# MKV10Z7 register map
File version: 1.6
Registers are 32-bit, read-write, reset 0x0 unless marked. A register's access mark holds for its fields unless they carry their own. Offsets are from the block's base; [hi:lo] are bit positions; {n}, {i} and the like mark numbered series; 'fields as' and 'values as' point back to an identical list.

## SIM — System Integration Module
Base 0x40047000; register names take the prefix SIM_
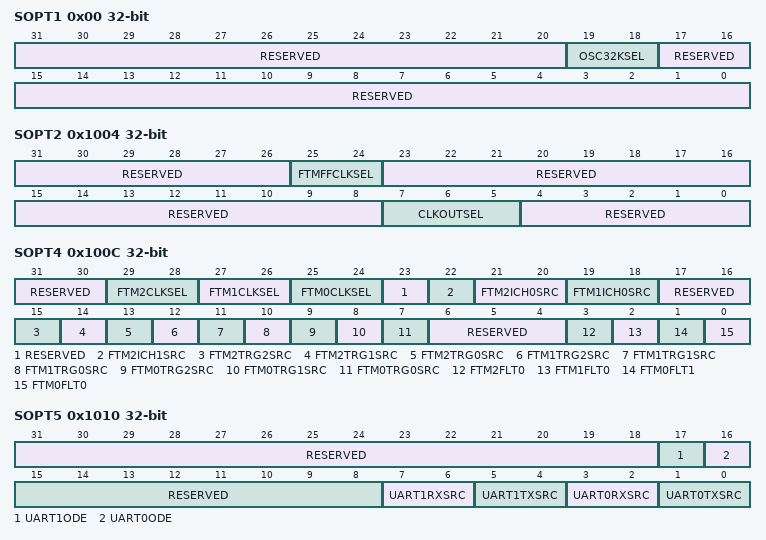
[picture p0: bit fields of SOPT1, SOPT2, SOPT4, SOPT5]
0x00 SOPT1 — System Options Register 1
  [31:20] RESERVED ro
  [19:18] OSC32KSEL — 32K Oscillator Clock Select
    0=System oscillator (OSC32KCLK); 3=LPO 1 kHz
  [17:0] RESERVED ro
0x1004 SOPT2 — System Options Register 2
  [31:26] RESERVED ro
  [25:24] FTMFFCLKSEL — FTM Fixed Frequency Clock Select
    0=MCGFFCLK; 1=MCGIRCLK; 2=OSCERCLK; 3=MCGFFCLK
  [23:8] RESERVED ro
  [7:5] CLKOUTSEL — CLKOUT Select
    2=Bus clock; 3=LPO clock (1 kHz); 4=MCGIRCLK; 6=OSCERCLK
  [4:0] RESERVED ro
0x100C SOPT4 — System Options Register 4
  [31:30] RESERVED ro
  [29:28] FTM2CLKSEL — FTM2 External Clock Pin Select
    0=FTM2 external clock driven by FTM_CLKIN0 pin; 1=FTM2 external clock driven by FTM_CLKIN1 pin; 2=FTM2 external clock driven by FTM_CLKIN2 pin
  [27:26] FTM1CLKSEL — FTM1 External Clock Pin Select
    0=FTM1 external clock driven by FTM_CLKIN0 pin; 1=FTM1 external clock driven by FTM_CLKIN1 pin; 2=FTM1 external clock driven by FTM_CLKIN2 pin
  [25:24] FTM0CLKSEL — FTM0 External Clock Pin Select
    0=FTM0 external clock driven by FTM_CLKIN0 pin; 1=FTM0 external clock driven by FTM_CLKIN1 pin; 2=FTM0 external clock driven by FTM_CLKIN2 pin
  [23] RESERVED ro
  [22] FTM2ICH1SRC — FTM2 Channel 1 Input Capture Source Select
    0=FTM2_CH1 pin is fed to FTM2 CH1; 1=FTM2_CH1 pin XOR FTM2_CH0 pin XOR FTM1_CH1 pin is fed to FTM2 CH1 If this field is set, then the three input pins feed FTM2 channel 1 input capture. In this case, FTM1 channel 1 cannot be used for input capture of FTM1, as it has no pin. FTM1 channel1 can be used for Output Compare mode of FTM1, though without an output.
  [21:20] FTM2ICH0SRC — FTM2 Channel 0 Input Capture Source Select
    0=FTM2_CH0 signal; 1=CMP0 output; 2=CMP1 output
  [19:18] FTM1ICH0SRC — FTM1 Channel 0 Input Capture Source Select
    0=FTM1_CH0 signal; 1=CMP0 output; 2=CMP1 output
  [17:16] RESERVED ro
  [15] FTM2TRG2SRC — FlexTimer 2 Hardware Trigger 2 Source Select
    0=HSCMP0 output drives FTM2 hardware trigger 2; 1=HSCMP1 output drives FTM2 hardware trigger 2
  [14] FTM2TRG1SRC — FlexTimer 2 Hardware Trigger 1 Source Select
    0=PDB output trigger 1 drives FTM2 hardware trigger 1; 1=FTM1 channel match drives FTM2 hardware trigger 1
  [13] FTM2TRG0SRC — FlexTimer 2 Hardware Trigger 0 Source Select
    0=HSCMP0 output drives FTM2 hardware trigger 0; 1=FTM0 channel match drives FTM2 hardware trigger 0
  [12] FTM1TRG2SRC — FlexTimer 1 Hardware Trigger 2 Source Select
    0=HSCMP0 output drives FTM1 hardware trigger 2; 1=HSCMP1 output drives FTM1 hardware trigger 2
  [11] FTM1TRG1SRC — FlexTimer 1 Hardware Trigger 1 Source Select
    0=PDB channel 1 trigger drives FTM1 hardware trigger 1; 1=FTM2 channel match drives FTM1 hardware trigger 1
  [10] FTM1TRG0SRC — FlexTimer 1 Hardware Trigger 0 Source Select
    0=HSCMP0 output drives FTM1 hardware trigger 0; 1=FTM0 channel match drives FTM1 hardware trigger 0
  [9] FTM0TRG2SRC — FlexTimer 0 Hardware Trigger 2 Source Select
    0=HSCMP0 output drives FTM0 hardware trigger 2; 1=HSCMP1 output drives FTM0 hardware trigger 2
  [8] FTM0TRG1SRC — FlexTimer 0 Hardware Trigger 1 Source Select
    0=PDB channel 1 trigger drives FTM0 hardware trigger 1; 1=FTM2 channel match drives FTM0 hardware trigger 1
  [7] FTM0TRG0SRC — FlexTimer 0 Hardware Trigger 0 Source Select
    0=HSCMP0 output drives FTM0 hardware trigger 0; 1=FTM1 channel match drives FTM0 hardware trigger 0
  [6:4] RESERVED ro
  [3] FTM2FLT0 — FTM2 Fault 0 Select
    0=FTM2_FLT0 pin; 1=CMP0 out
  [2] FTM1FLT0 — FTM1 Fault 0 Select
    0=FTM1_FLT0 pin; 1=CMP0 out
  [1] FTM0FLT1 — FTM0 Fault 1 Select
    0=FTM0_FLT1 pin; 1=CMP1 out
  [0] FTM0FLT0 — FTM0 Fault 0 Select
    0=FTM0_FLT0 pin; 1=CMP0 out
0x1010 SOPT5 — System Options Register 5
  [31:18] RESERVED
  [17] UART1ODE — UART1 Open Drain Enable
    0=Open drain is disabled on UART1; 1=Open drain is enabled on UART1
  [16] UART0ODE — UART0 Open Drain Enable
    0=Open drain is disabled on UART0; 1=Open drain is enabled on UART0
  [15:8] RESERVED ro
  [7:6] UART1RXSRC — UART 1 Receive Data Source Select
    0=UART1_RX pin; 1=CMP0; 2=CMP1
  [5:4] UART1TXSRC — UART 1 Transmit Data Source Select
    0=UART1_TX pin; 1=UART1_TX pin modulated with FTM1 channel 0 output; 2=UART1_TX pin modulated with FTM2 channel 0 output
  [3:2] UART0RXSRC — UART 0 Receive Data Source Select
    0=UART0_RX pin; 1=CMP0; 2=CMP1
  [1:0] UART0TXSRC — UART 0 Transmit Data Source Select
    0=UART0_TX pin; 1=UART0_TX pin modulated with FTM1 channel 0 output; 2=UART0_TX pin modulated with FTM2 channel 0 output
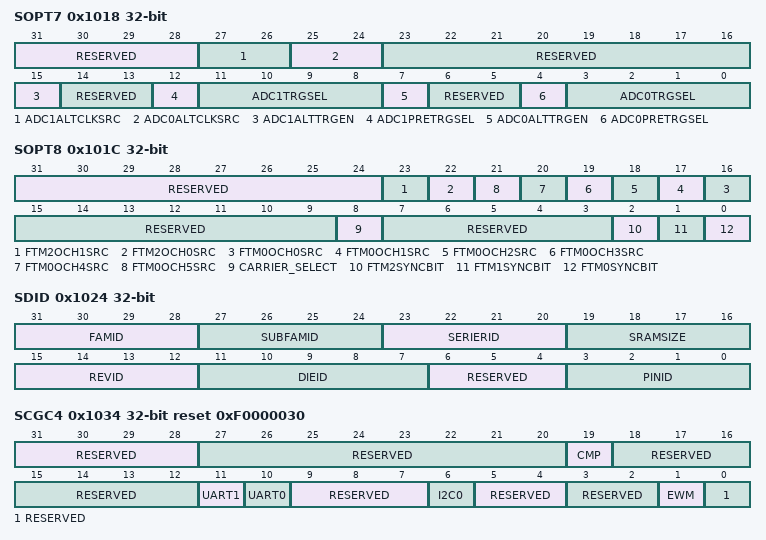
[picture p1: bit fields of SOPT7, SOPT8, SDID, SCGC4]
0x1018 SOPT7 — System Options Register 7
  [31:28] RESERVED ro
  [27:26] ADC1ALTCLKSRC — ADC1 ALT Clock Source Select
    0=OUTDIV5 output; 1=MCGIRCLK; 2=OSCERCLK
  [25:24] ADC0ALTCLKSRC — ADC0 ALT Clock Source Select
    0=OUTDIV5 output; 1=MCGIRCLK; 2=OSCERCLK
  [23:16] RESERVED ro
  [15] ADC1ALTTRGEN — ADC1 Alternate Trigger Enable
    0=PDB trigger selected for ADC1; 1=Alternate trigger selected for ADC1 as defined by ADC1TRGSEL
  [14:13] RESERVED ro
  [12] ADC1PRETRGSEL — ADC1 Pre-trigger Select
    0=Pre-trigger A for ADC1. Clearing this field will result in ADHWTSA=1 and ADHWTSB=0.; 1=Pre-trigger B for ADC1. Setting this bit will result in ADHWTSA=0 and ADHWTSB=1.
  [11:8] ADC1TRGSEL — ADC1 Trigger Select
    0=External trigger pin input (PDB0_EXTRG); 1=HSCMP0 output; 2=HSCMP1 output; {v}=DMA channel {v-4} transfer last write complete (v=4..7); 8=FTM0 overflow; 9=FTM1 overflow; 10=FTM2 overflow; 14=LPTMR0 trigger
  [7] ADC0ALTTRGEN — ADC0 Alternate Trigger Enable
    0=PDB trigger selected for ADC0; 1=Alternate trigger selected for ADC0 as defined by ADC0TRGSEL
  [6:5] RESERVED ro
  [4] ADC0PRETRGSEL — ADC0 Pre-trigger Select
    0=Pre-trigger A for ADC0. Clearing this field will result in ADHWTSA=1 and ADHWTSB=0.; 1=Pre-trigger B for ADC0. Setting this bit will result in ADHWTSA=0 and ADHWTSB=1.
  [3:0] ADC0TRGSEL — ADC0 Trigger Select
    values as ADC1TRGSEL
0x101C SOPT8 — System Options Register 8
  [31:24] RESERVED ro
  [23] FTM2OCH1SRC — FTM2 channel 1 output PWM/OCMP mode source select
    0=FTM2CH1 pin is the output of FTM2 channel 1 PWM/OCMP; 1=FTM2CH1 pin is the output of FTM2 channel 1 PWM/OCMP modulating the carrier frequency, as per CARRIER_SELECT
  [22] FTM2OCH0SRC — FTM2 channel 0 output PWM/OCMP mode source select
    0=FTM2CH0 pin is the output of FTM2 channel 0 PWM/OCMP; 1=FTM2CH0 pin is the output of FTM2 channel 0 PWM/OCMP modulating the carrier frequency, as per CARRIER_SELECT
  [n+16] FTM0OCH{n}SRC (n=0..5) — FTM0 channel {n} output PWM/OCMP mode source select
    0=FTM0CH{n} pin is the output of FTM0 channel {n} PWM/OCMP; 1=FTM0CH{n} pin is the output of FTM0 channel {n} PWM/OCMP modulating the carrier frequency, as per CARRIER_SELECT
  [15:9] RESERVED
  [8] CARRIER_SELECT — Carrier frequency selection for FTM0/2 output channel
    0=FTM1_CH1 output provides the carrier signal for Timer Modulation mode; 1=LPTMR0 prescaler output provides the carrier signal for Timer Modulation mode
  [7:3] RESERVED ro
  [2] FTM2SYNCBIT — FlexTimer 2 Hardware Trigger 0 configure by software
    0=No effect to FTM2; this allows the hardware trigger options to function as expected. See SOPT4[FTM2TRG0SRC].; 1=If TRIG0 is enabled, this refreshes the FTM2CNTIN and all buffered registers of the FTM2 (must write 0 first then write 1); this masks the hardware trigger
  [1] FTM1SYNCBIT — FlexTimer 1 Hardware Trigger 0 configure by software
    0=No effect to FTM1; this allows the hardware trigger options to function as expected. See SOPT4[FTM1TRG0SRC].; 1=If TRIG0 enabled, this refreshes the FTM1CNTIN and all buffered registers of the FTM1 (must write 0 first then write 1); this masks the hardware trigger
  [0] FTM0SYNCBIT — FlexTimer 0 Hardware Trigger 0 configure by software
    0=No effect to FTM0; this allow the hardware trigger options to function as expected. See SOPT4[FTM0TRG0SRC].; 1=If TRIG0 enabled, this refreshes the FTM0CNTIN and all buffered registers of the FTM0 (must write 0 first then write 1); this masks the hardware trigger
0x1024 SDID ro reset not defined — System Device Identification Register
  [31:28] FAMID — V-Family ID
    1=MKV10Zx
  [27:24] SUBFAMID — V Sub-family ID
    0=MKV10xxxx
  [23:20] SERIERID — Series ID
    6=V-family - Motor control
  [19:16] SRAMSIZE — System SRAM Size
    3=4 KB; 4=8 KB
  [15:12] REVID — Device revision number
  [11:7] DIEID — Device die number
  [6:4] RESERVED
  [3:0] PINID — Pincount identification
    2=32-pin; 3=44-pin; 4=48-pin
0x1034 SCGC4 reset 0xF0000030 — System Clock Gating Control Register 4
  [31:28] RESERVED ro
  [27:20] RESERVED ro
  [19] CMP — Comparator Clock Gate Control
    0=Clock disabled; 1=Clock enabled
  [18:12] RESERVED ro
  [11] UART1 — UART1 Clock Gate Control
    0=Clock disabled; 1=Clock enabled
  [10] UART0 — UART0 Clock Gate Control
    0=Clock disabled; 1=Clock enabled
  [9:7] RESERVED ro
  [6] I2C0 — I2C0 Clock Gate Control
    0=Clock disabled; 1=Clock enabled
  [5:4] RESERVED ro
  [3:2] RESERVED ro
  [1] EWM — EWM Clock Gate Control
    0=Clock disabled; 1=Clock enabled
  [0] RESERVED ro
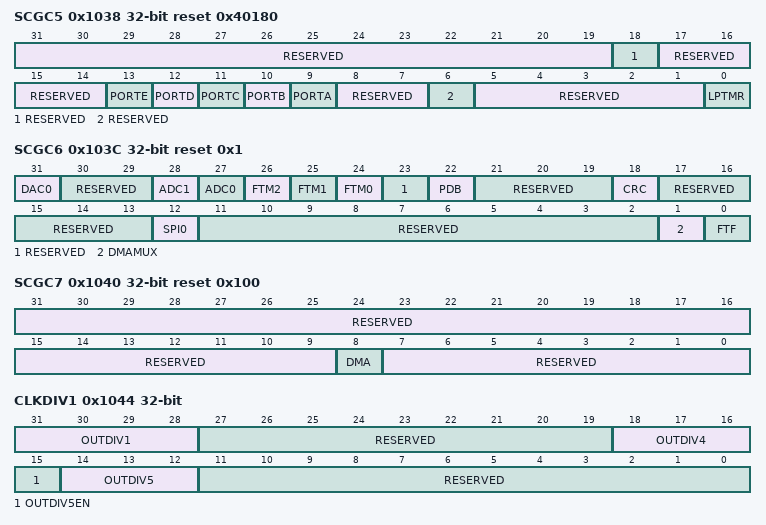
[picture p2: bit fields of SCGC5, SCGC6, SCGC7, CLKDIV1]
0x1038 SCGC5 reset 0x40180 — System Clock Gating Control Register 5
  [31:19] RESERVED ro
  [18] RESERVED ro
  [17:14] RESERVED ro
  [13] PORTE — Port E Clock Gate Control
    0=Clock disabled; 1=Clock enabled
  [12] PORTD — Port D Clock Gate Control
    0=Clock disabled; 1=Clock enabled
  [11] PORTC — Port C Clock Gate Control
    0=Clock disabled; 1=Clock enabled
  [10] PORTB — Port B Clock Gate Control
    0=Clock disabled; 1=Clock enabled
  [9] PORTA — Port A Clock Gate Control
    0=Clock disabled; 1=Clock enabled
  [8:7] RESERVED ro
  [6] RESERVED ro
  [5:1] RESERVED ro
  [0] LPTMR — Low Power Timer Clock Gate Control
    0=Access disabled; 1=Access enabled
0x103C SCGC6 reset 0x1 — System Clock Gating Control Register 6
  [31] DAC0 — DAC0 Clock Gate Control
    0=Clock disabled; 1=Clock enabled
  [30:29] RESERVED ro
  [28] ADC1 — ADC1 Clock Gate Control
    0=Clock disabled; 1=Clock enabled
  [27] ADC0 — ADC0 Clock Gate Control
    0=Clock disabled; 1=Clock enabled
  [26] FTM2 — FTM2 Clock Gate Control
    0=Clock disabled; 1=Clock enabled
  [25] FTM1 — FTM1 Clock Gate Control
    0=Clock disabled; 1=Clock enabled
  [24] FTM0 — FTM0 Clock Gate Control
    0=Clock disabled; 1=Clock enabled
  [23] RESERVED ro
  [22] PDB — PDB Clock Gate Control
    0=Clock disabled; 1=Clock enabled
  [21:19] RESERVED ro
  [18] CRC — CRC Clock Gate Control
    0=Clock disabled; 1=Clock enabled
  [17:13] RESERVED ro
  [12] SPI0 — SPI0 Clock Gate Control
    0=Clock disabled; 1=Clock enabled
  [11:2] RESERVED ro
  [1] DMAMUX — DMA Mux Clock Gate Control
    0=Clock disabled; 1=Clock enabled
  [0] FTF — Flash Memory Clock Gate Control
    0=Clock disabled; 1=Clock enabled
0x1040 SCGC7 reset 0x100 — System Clock Gating Control Register 7
  [31:9] RESERVED ro
  [8] DMA — DMA Clock Gate Control
    0=Clock disabled; 1=Clock enabled
  [7:0] RESERVED ro
0x1044 CLKDIV1 reset not defined — System Clock Divider Register 1
  [31:28] OUTDIV1 — Clock 1 Output Divider Value
    {v}=Divide-by-{v+1} (v=0..15)
  [27:19] RESERVED ro
  [18:16] OUTDIV4 — Clock 4 Output Divider Value
    {v}=Divide-by-{v+1} (v=0..7)
  [15] OUTDIV5EN — OUTDIV5 Divider Control
    0=OUTDIV5 disabled; 1=OUTDIV5 enabled
  [14:12] OUTDIV5 — Clock 5 Output Divider Value
    {v}=Divide-by-{v+1} (v=0..7)
  [11:0] RESERVED ro
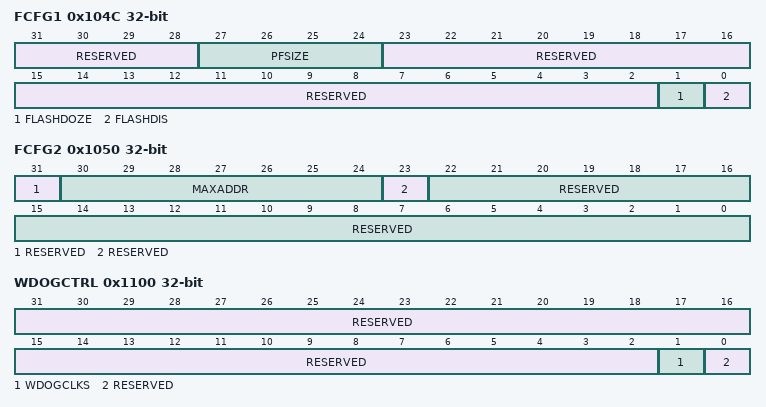
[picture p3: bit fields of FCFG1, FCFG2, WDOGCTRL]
0x104C FCFG1 reset not defined — Flash Configuration Register 1
  [31:28] RESERVED ro
  [27:24] PFSIZE ro — Program Flash Size
    0=8 KB of program flash memory, 0.25 KB protection region; 1=16 KB of program flash memory, 0.5 KB protection region; 3=32 KB of program flash memory, 1 KB protection region; 5=64 KB of program flash memory, 2 KB protection region; 7=128 KB of program flash memory, 4 KB protection region; 9=256 KB of program flash memory, 4 KB protection region; 15=32 KB of program flash memory, 1 KB protection region
  [23:2] RESERVED ro
  [1] FLASHDOZE
    0=Flash remains enabled during Doze mode; 1=Flash is disabled for the duration of Doze mode
  [0] FLASHDIS — Flash Disable
    0=Flash is enabled; 1=Flash is disabled
0x1050 FCFG2 ro reset not defined — Flash Configuration Register 2
  [31] RESERVED
  [30:24] MAXADDR — Max address block
  [23] RESERVED
  [22:0] RESERVED
0x1058 UIDMH ro reset not defined — Unique Identification Register Mid-High
  [31:0] UID — Unique Identification
0x105C UIDML ro reset not defined — Unique Identification Register Mid Low
  [31:0] UID — Unique Identification
0x1060 UIDL ro reset not defined — Unique Identification Register Low
  [31:0] UID — Unique Identification
0x1100 WDOGCTRL — WDOG Control Register
  [31:2] RESERVED ro
  [1] WDOGCLKS — WDOG Clock Select
    0=Internal 1 kHz clock is source to WDOG; 1=MCGIRCLK is source to WDOG
  [0] RESERVED ro
